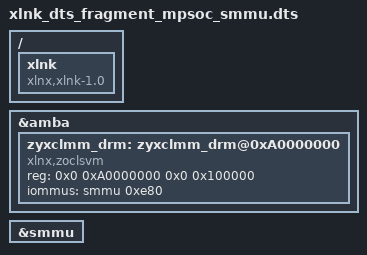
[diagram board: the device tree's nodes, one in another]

/{
	xlnk {
		compatible = "xlnx,xlnk-1.0";
	};
};

&amba {
        zyxclmm_drm: zyxclmm_drm@0xA0000000 {
                compatible = "xlnx,zoclsvm";
                status = "okay";
                reg = <0x0 0xA0000000 0x0 0x100000>;
                #stream-id-cells = <1>;
                iommus = <&smmu 0xe80>;
        };
};

&smmu {
    status = "okay";
};

